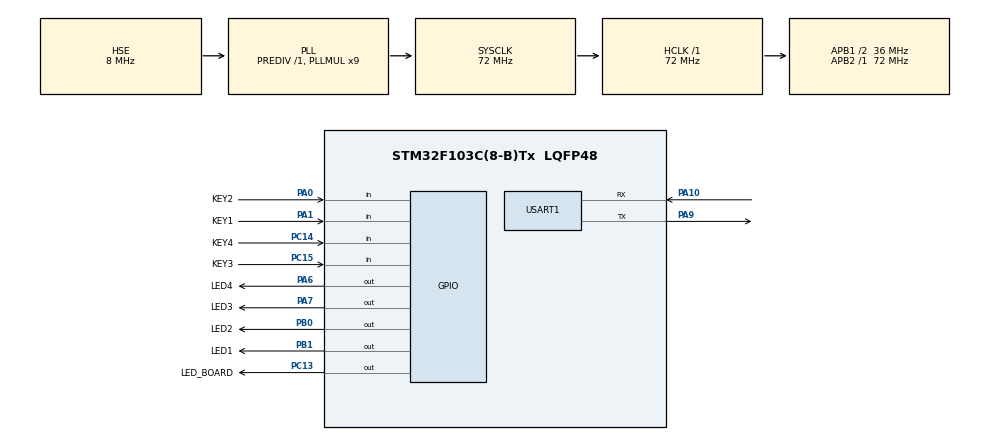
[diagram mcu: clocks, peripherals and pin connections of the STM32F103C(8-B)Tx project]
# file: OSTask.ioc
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FREERTOS.Queues01=ButtonQueue,1,uint8_t,0,Dynamic,NULL,NULL
FREERTOS.Tasks01=defaultTask,24,128,StartDefaultTask,Default,NULL,Dynamic,NULL,NULL;ButtonTask,24,128,vButtonTask,Default,NULL,Dynamic,NULL,NULL;LEDTask,8,128,vLEDTask,Default,NULL,Dynamic,NULL,NULL;myTask01,8,128,StartTask04,Default,NULL,Dynamic,NULL,NULL
Mcu.Family=STM32F1
Mcu.Name=STM32F103C(8-B)Tx
Mcu.Package=LQFP48
NVIC.PriorityGroup=NVIC_PRIORITYGROUP_4
NVIC.TIM1_UP_IRQn=true\:5\:0\:false\:false\:true\:true\:true\:true\:true
NVIC.TIM4_IRQn=true\:15\:0\:false\:false\:true\:false\:false\:true\:true
NVIC.TimeBase=TIM4_IRQn
NVIC.TimeBaseIP=TIM4
PA0-WKUP.GPIO_Label=KEY2
PA0-WKUP.GPIO_PuPd=GPIO_PULLUP
PA0-WKUP.Signal=GPIO_Input
PA1.GPIO_Label=KEY1
PA1.GPIO_PuPd=GPIO_PULLUP
PA1.Signal=GPIO_Input
PA10.Mode=Asynchronous
PA10.Signal=USART1_RX
PA13.Mode=Serial_Wire
PA13.Signal=SYS_JTMS-SWDIO
PA14.Mode=Serial_Wire
PA14.Signal=SYS_JTCK-SWCLK
PA6.GPIO_Label=LED4
PA6.GPIO_PuPd=GPIO_NOPULL
PA6.PinState=GPIO_PIN_SET
PA6.Signal=GPIO_Output
PA7.GPIO_Label=LED3
PA7.PinState=GPIO_PIN_SET
PA7.Signal=GPIO_Output
PA9.Mode=Asynchronous
PA9.Signal=USART1_TX
PB0.GPIO_Label=LED2
PB0.PinState=GPIO_PIN_SET
PB0.Signal=GPIO_Output
PB1.GPIO_Label=LED1
PB1.PinState=GPIO_PIN_SET
PB1.Signal=GPIO_Output
PC13-TAMPER-RTC.GPIO_Label=LED_BOARD
PC13-TAMPER-RTC.GPIO_ModeDefaultOutputPP=GPIO_MODE_OUTPUT_PP
PC13-TAMPER-RTC.GPIO_PuPd=GPIO_NOPULL
PC13-TAMPER-RTC.PinState=GPIO_PIN_RESET
PC13-TAMPER-RTC.Signal=GPIO_Output
PC14-OSC32_IN.GPIO_Label=KEY4
PC14-OSC32_IN.GPIO_PuPd=GPIO_PULLUP
PC14-OSC32_IN.Signal=GPIO_Input
PC15-OSC32_OUT.GPIO_Label=KEY3
PC15-OSC32_OUT.GPIO_PuPd=GPIO_PULLUP
PC15-OSC32_OUT.Signal=GPIO_Input
PD0-OSC_IN.Mode=HSE-External-Oscillator
PD0-OSC_IN.Signal=RCC_OSC_IN
PD1-OSC_OUT.Mode=HSE-External-Oscillator
PD1-OSC_OUT.Signal=RCC_OSC_OUT
ProjectManager.HeapSize=0x200
ProjectManager.StackSize=0x400
ProjectManager.TargetToolchain=CMake
RCC.AHBFreq_Value=72000000
RCC.APB1CLKDivider=RCC_HCLK_DIV2
RCC.APB1Freq_Value=36000000
RCC.APB1TimFreq_Value=72000000
RCC.APB2Freq_Value=72000000
RCC.APB2TimFreq_Value=72000000
RCC.HCLKFreq_Value=72000000
RCC.PLLMUL=RCC_PLL_MUL9
RCC.PLLSourceVirtual=RCC_PLLSOURCE_HSE
RCC.SYSCLKFreq_VALUE=72000000
RCC.SYSCLKSource=RCC_SYSCLKSOURCE_PLLCLK
RCC.USBFreq_Value=72000000
TIM1.AutoReloadPreload=TIM_AUTORELOAD_PRELOAD_ENABLE
TIM1.Period=1000 - 1
TIM1.Prescaler=72 - 1
USART1.VirtualMode=VM_ASYNC
VP_FREERTOS_VS_CMSIS_V2.Mode=CMSIS_V2
VP_SYS_VS_tim4.Mode=TIM4
VP_TIM1_VS_ClockSourceINT.Mode=Internal
board=custom

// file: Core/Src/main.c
/* USER CODE BEGIN Header */
/**
  ******************************************************************************
  * @file           : main.c
  * @brief          : Main program body
  ******************************************************************************
  * @attention
  *
  * Copyright (c) 2026 STMicroelectronics.
  * All rights reserved.
  *
  * This software is licensed under terms that can be found in the LICENSE file
  * in the root directory of this software component.
  * If no LICENSE file comes with this software, it is provided AS-IS.
  *
  ******************************************************************************
  */
/* USER CODE END Header */
#include "main.h"
#include "cmsis_os.h"
#include "tim.h"
#include "usart.h"
#include "gpio.h"

void SystemClock_Config(void);
void MX_FREERTOS_Init(void);

int main(void)
{

  /* MCU Configuration--------------------------------------------------------*/

  /* Reset of all peripherals, Initializes the Flash interface and the Systick. */
  HAL_Init();

  /* Configure the system clock */
  SystemClock_Config();

  /* Initialize all configured peripherals */
  MX_GPIO_Init();
  MX_USART1_UART_Init();
  MX_TIM1_Init();
  /* USER CODE BEGIN 2 */
  // 减少函数的嵌套层数 可以解决栈空间大小不够的问题 , 最重要: 就是要减少任务内的临时变量还有函数的嵌套层数
  // 申请的空间大于总堆空间的时候会出现 , 任务执行失败
  /* USER CODE END 2 */

  /* Init scheduler */
  osKernelInitialize();  /* Call init function for freertos objects (in cmsis_os2.c) */
  MX_FREERTOS_Init();

  /* Start scheduler */
  osKernelStart();

  /* We should never get here as control is now taken by the scheduler */

  /* Infinite loop */
  while (1) {

  }
}

void SystemClock_Config(void)
{
  RCC_OscInitTypeDef RCC_OscInitStruct = {0};
  RCC_ClkInitTypeDef RCC_ClkInitStruct = {0};

  /** Initializes the RCC Oscillators according to the specified parameters
  * in the RCC_OscInitTypeDef structure.
  */
  RCC_OscInitStruct.OscillatorType = RCC_OSCILLATORTYPE_HSE;
  RCC_OscInitStruct.HSEState = RCC_HSE_ON;
  RCC_OscInitStruct.HSEPredivValue = RCC_HSE_PREDIV_DIV1;
  RCC_OscInitStruct.HSIState = RCC_HSI_ON;
  RCC_OscInitStruct.PLL.PLLState = RCC_PLL_ON;
  RCC_OscInitStruct.PLL.PLLSource = RCC_PLLSOURCE_HSE;
  RCC_OscInitStruct.PLL.PLLMUL = RCC_PLL_MUL9;
  if (HAL_RCC_OscConfig(&RCC_OscInitStruct) != HAL_OK)
  {
    Error_Handler();
  }

  /** Initializes the CPU, AHB and APB buses clocks
  */
  RCC_ClkInitStruct.ClockType = RCC_CLOCKTYPE_HCLK|RCC_CLOCKTYPE_SYSCLK
                              |RCC_CLOCKTYPE_PCLK1|RCC_CLOCKTYPE_PCLK2;
  RCC_ClkInitStruct.SYSCLKSource = RCC_SYSCLKSOURCE_PLLCLK;
  RCC_ClkInitStruct.AHBCLKDivider = RCC_SYSCLK_DIV1;
  RCC_ClkInitStruct.APB1CLKDivider = RCC_HCLK_DIV2;
  RCC_ClkInitStruct.APB2CLKDivider = RCC_HCLK_DIV1;

  if (HAL_RCC_ClockConfig(&RCC_ClkInitStruct, FLASH_LATENCY_2) != HAL_OK)
  {
    Error_Handler();
  }
}

void HAL_TIM_PeriodElapsedCallback(TIM_HandleTypeDef *htim)
{
  if (htim->Instance == TIM4)
  {
    HAL_IncTick();
  }
}

void Error_Handler(void)
{
  __disable_irq();
  while (1) {
  }
}

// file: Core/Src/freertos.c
/* USER CODE BEGIN Header */
/**
  ******************************************************************************
  * File Name          : freertos.c
  * Description        : Code for freertos applications
  ******************************************************************************
  * @attention
  *
  * Copyright (c) 2026 STMicroelectronics.
  * All rights reserved.
  *
  * This software is licensed under terms that can be found in the LICENSE file
  * in the root directory of this software component.
  * If no LICENSE file comes with this software, it is provided AS-IS.
  *
  ******************************************************************************
  */
/* USER CODE END Header */

#include "FreeRTOS.h"
#include "task.h"
#include "main.h"
#include "cmsis_os.h"

/* USER CODE BEGIN Includes */
#include "userTask.h"
/* USER CODE END Includes */

/* Definitions for defaultTask */
osThreadId_t defaultTaskHandle;
const osThreadAttr_t defaultTask_attributes = {
  .name = "defaultTask",
  .stack_size = 128 * 4,
  .priority = (osPriority_t) osPriorityNormal,
};
/* Definitions for ButtonTask */
osThreadId_t ButtonTaskHandle;
const osThreadAttr_t ButtonTask_attributes = {
  .name = "ButtonTask",
  .stack_size = 128 * 4,
  .priority = (osPriority_t) osPriorityNormal,
};
/* Definitions for LEDTask */
osThreadId_t LEDTaskHandle;
const osThreadAttr_t LEDTask_attributes = {
  .name = "LEDTask",
  .stack_size = 128 * 4,
  .priority = (osPriority_t) osPriorityLow,
};
/* Definitions for myTask01 */
osThreadId_t myTask01Handle;
const osThreadAttr_t myTask01_attributes = {
  .name = "myTask01",
  .stack_size = 128 * 4,
  .priority = (osPriority_t) osPriorityLow,
};
/* Definitions for ButtonQueue */
osMessageQueueId_t ButtonQueueHandle;
const osMessageQueueAttr_t ButtonQueue_attributes = {
  .name = "ButtonQueue"
};

void StartDefaultTask(void *argument);
void vButtonTask(void *argument);
void vLEDTask(void *argument);
void StartTask04(void *argument);

void MX_FREERTOS_Init(void); /* (MISRA C 2004 rule 8.1) */

void MX_FREERTOS_Init(void) {

  /* Create the queue(s) */
  /* creation of ButtonQueue */
  ButtonQueueHandle = osMessageQueueNew (1, sizeof(uint8_t), &ButtonQueue_attributes);

  /* Create the thread(s) */
  /* creation of defaultTask */
  defaultTaskHandle = osThreadNew(StartDefaultTask, NULL, &defaultTask_attributes);

  /* creation of ButtonTask */
  ButtonTaskHandle = osThreadNew(vButtonTask, NULL, &ButtonTask_attributes);

  /* creation of LEDTask */
  LEDTaskHandle = osThreadNew(vLEDTask, NULL, &LEDTask_attributes);

  /* creation of myTask01 */
  myTask01Handle = osThreadNew(StartTask04, NULL, &myTask01_attributes);

}

void StartDefaultTask(void *argument)
{
  for (;;) {
    osDelay(1);
  }
}

void vButtonTask(void *argument)
{
  for(;;)
  {
    osDelay(1);
  }
}

void vLEDTask(void *argument)
{
  for(;;)
  {
    osDelay(1);
  }
}

void StartTask04(void *argument)
{
  /* USER CODE BEGIN StartTask04 */
  /* Infinite loop */
  for (;;) {
    vUartTask_C();
  }
  /* USER CODE END StartTask04 */
}
